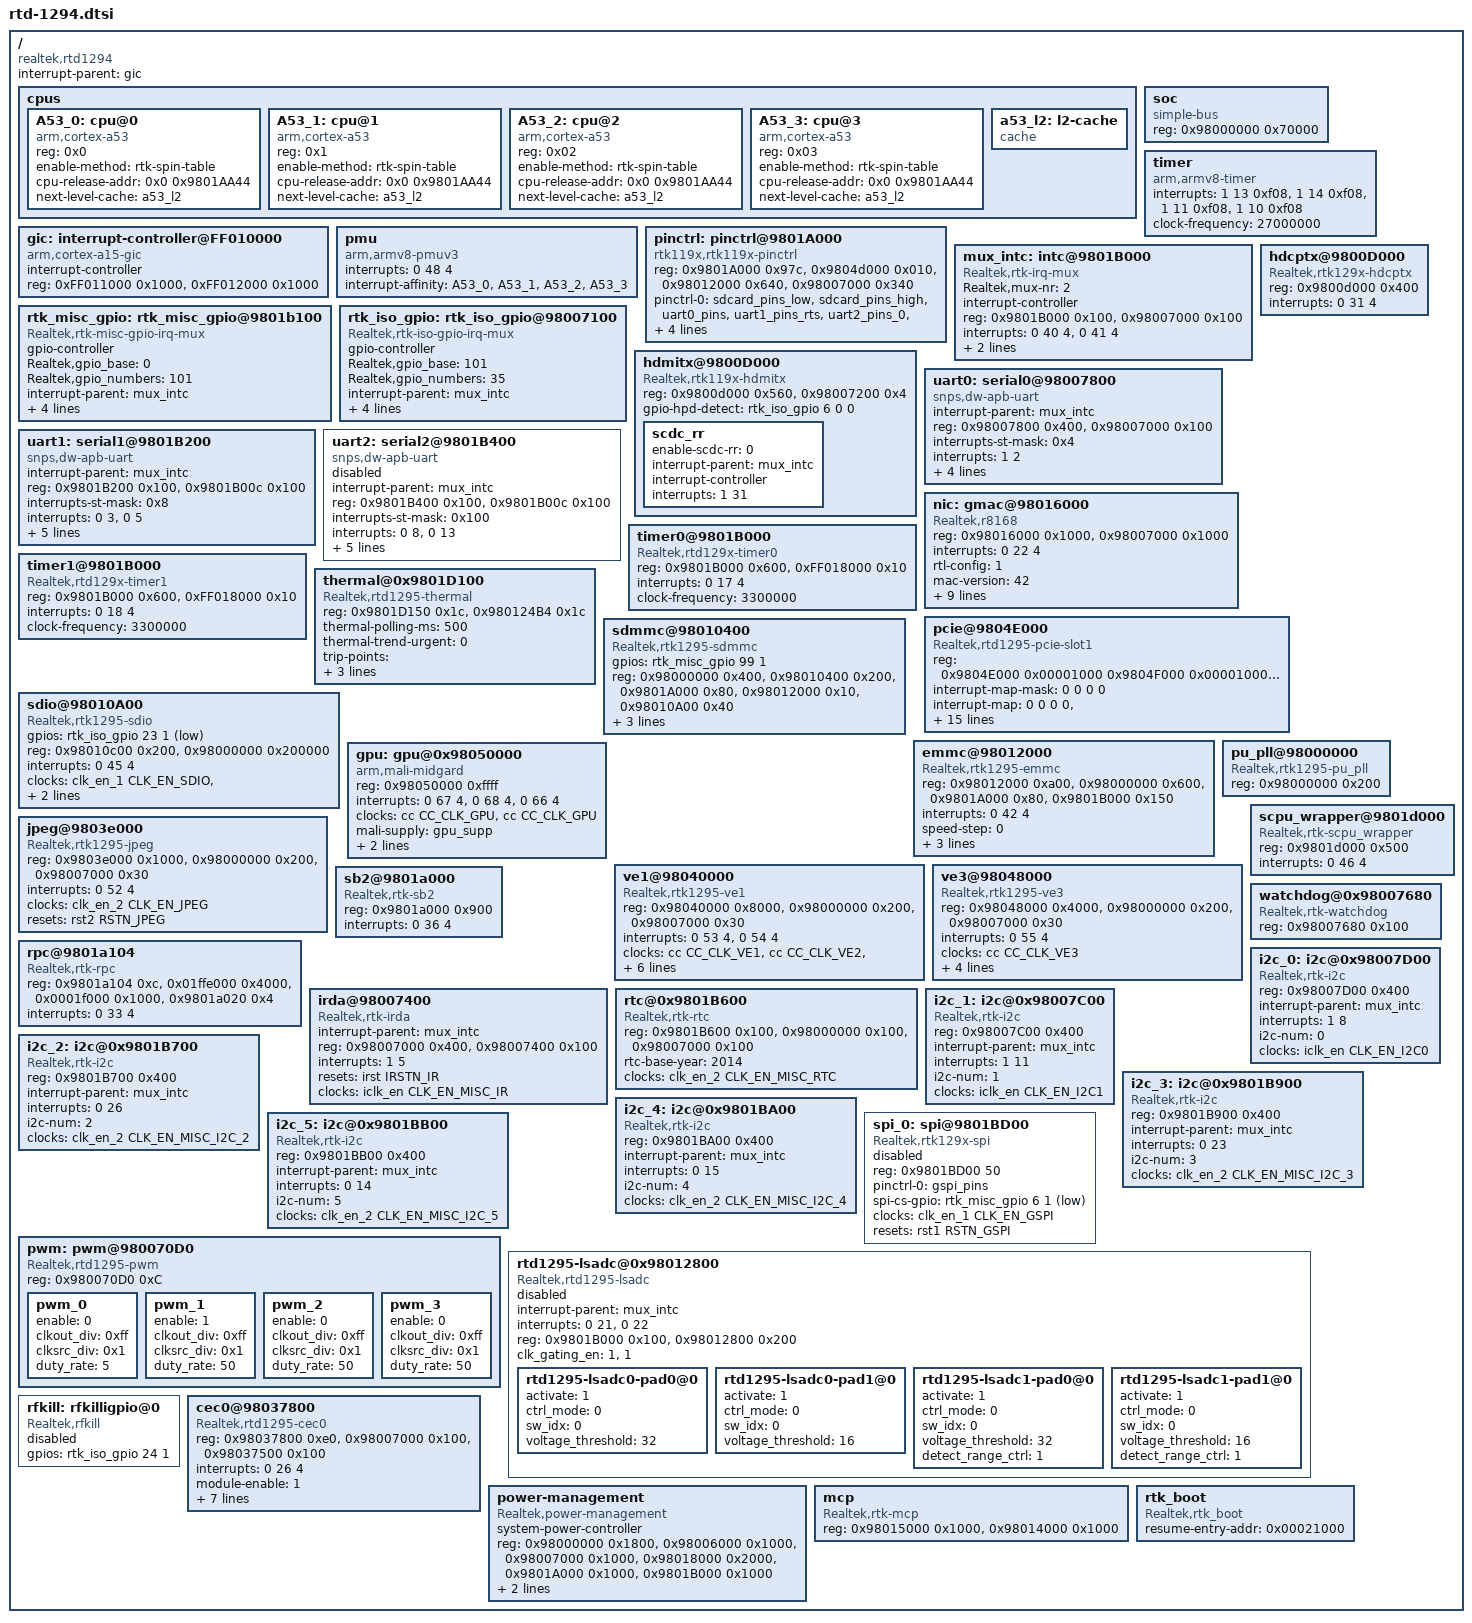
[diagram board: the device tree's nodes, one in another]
#include <dt-bindings/interrupt-controller/irq.h>
#include <dt-bindings/interrupt-controller/arm-gic.h>
/include/ "rtd-1295-pinctrl.dtsi"
/include/ "rtd-1295-irT377.dtsi"
/include/ "rtd-1294-usb.dtsi"
/include/ "rtd-129x-gpu-dvfs.dtsi"
#include "rtd-129x-common.dtsi"
/include/ "rtd-129x-dcsys-debug.dtsi"

/{

    compatible = "realtek,rtd1294";
    interrupt-parent = <&gic>;
    #address-cells = <1>;
    #size-cells = <1>;

    cpus {
        #address-cells = <1>;
        #size-cells = <0>;

        A53_0: cpu@0 {
            device_type = "cpu";
            compatible = "arm,cortex-a53", "arm,armv8";
            reg = <0x0>;
            /*enable-method = "psci";*/
            enable-method = "rtk-spin-table";
            cpu-release-addr = <0x0 0x9801AA44>;
            next-level-cache = <&a53_l2>;
        };

        A53_1: cpu@1 {
            device_type = "cpu";
            compatible = "arm,cortex-a53", "arm,armv8";
            reg = <0x1>;
            /*enable-method = "psci";*/
            enable-method = "rtk-spin-table";
            cpu-release-addr = <0x0 0x9801AA44>;
            next-level-cache = <&a53_l2>;
        };

        A53_2: cpu@2 {
            device_type = "cpu";
            compatible = "arm,cortex-a53", "arm,armv8";
            reg = <0x02>;
            /*enable-method = "psci";*/
            enable-method = "rtk-spin-table";
            cpu-release-addr = <0x0 0x9801AA44>;
            next-level-cache = <&a53_l2>;
        };

        A53_3: cpu@3 {
            device_type = "cpu";
            compatible = "arm,cortex-a53", "arm,armv8";
            reg = <0x03>;
            /*enable-method = "psci";*/
            enable-method = "rtk-spin-table";
            cpu-release-addr = <0x0 0x9801AA44>;
            next-level-cache = <&a53_l2>;
        };

        a53_l2: l2-cache {
            compatible = "cache";
        };
    };

    soc {
        #address-cells = <1>;
        #size-cells = <1>;
        reg = <0x98000000 0x70000>;
        compatible = "simple-bus";
        device_type = "soc";
        ranges;
    };

    timer {
        compatible = "arm,armv8-timer";
        interrupts = <1 13 0xf08>,
                     <1 14 0xf08>,
                     <1 11 0xf08>,
                     <1 10 0xf08>;
        clock-frequency = <27000000>;
    };

    gic: interrupt-controller@FF010000 {
        compatible = "arm,cortex-a15-gic";
        #interrupt-cells = <3>;
        interrupt-controller;
        reg = <0xFF011000 0x1000>,
              <0xFF012000 0x1000>;
    };

    pmu {
        compatible = "arm,armv8-pmuv3";
        interrupts = <0 48 4>;
        interrupt-affinity = <&A53_0>,
                             <&A53_1>,
                             <&A53_2>,
                             <&A53_3>;
    };

    pinctrl: pinctrl@9801A000 {
        compatible = "rtk119x,rtk119x-pinctrl";
        reg = <0x9801A000 0x97c>, <0x9804d000 0x010>, <0x98012000 0x640>, <0x98007000 0x340>;
        #gpio-range-cells = <3>;

        pinctrl-names = "default";
        pinctrl-0 = <&sdcard_pins_low>,
                    <&sdcard_pins_high>,
                    <&uart0_pins>,
                    <&uart1_pins_rts>,
                    <&uart2_pins_0>,
                    <&i2c_pins_0>,
                    <&i2c_pins_1>,
                    <&i2c_pins_5>,
                    <&i2c_pins_6>,
                    <&pcie1_clk_pins>,
                    <&pcie2_clk_pins>,
                    <&rgmii0_pins>,
                    <&ir_rx_pins>,
                    <&ir_tx_pins>,
                    <&spdif_pins>,
                    <&pwm0_0_pins>,
                    <&etn_led_pins>;
        status = "okay";
    };

    mux_intc: intc@9801B000 {
        compatible = "Realtek,rtk-irq-mux";
        Realtek,mux-nr = <2>;
        #interrupt-cells = <2>;
        interrupt-controller;
        reg = <0x9801B000 0x100>, /* MISC_TOP MISC_ISO */
              <0x98007000 0x100>;
        interrupts = <0 40 4>, <0 41 4>;
        intr-status = <0xc>, <0x0>;
        intr-en = <0x80>, <0x40>;
        status = "okay";
    };

    rtk_misc_gpio: rtk_misc_gpio@9801b100 {
        compatible = "Realtek,rtk-misc-gpio-irq-mux";
        gpio-controller;
        #gpio-cells = <3>; /*must be the same with gpiochip.of_gpio_n_cells*/
        Realtek,gpio_base = <0>;
        Realtek,gpio_numbers = <101>;
        interrupt-parent = <&mux_intc>;
        #interrupt-cells = <1>;
        interrupt-controller;
        interrupts = <0 19>, <0 20>; /*GPIOA_INT   GPIODA_INT*/
        reg = <0x9801b000 0x100>, <0x9801b100 0x100>; /* MISC_SYS MISC_GPIO*/
        gpio-ranges = <&pinctrl 0 0 101>;
        status = "okay";
    };

    rtk_iso_gpio: rtk_iso_gpio@98007100 {
        compatible = "Realtek,rtk-iso-gpio-irq-mux";
        gpio-controller;
        #gpio-cells = <3>;
        Realtek,gpio_base = <101>;
        Realtek,gpio_numbers = <35>;
        interrupt-parent = <&mux_intc>;
        #interrupt-cells = <1>;
        interrupt-controller;
        interrupts = <1 19>, <1 20>; /*GPIOA_INT   GPIODA_INT*/
        reg = <0x98007000 0x100>, <0x98007100 0x100>; /* ISO_SYS ISO_GPIO*/
        gpio-ranges = <&pinctrl 0 101 35>;
        status = "okay";
    };

	hdmitx@9800D000 {
		compatible = "Realtek,rtk119x-hdmitx";
		reg = <0x9800d000 0x560>,<0x98007200 0x4>; /* HDMITX, I2C1_REQ_CTRL */
		gpio-hpd-detect = <&rtk_iso_gpio 6 0 0>; /* Hotplug detect pin */
		//gpio-audio-mute = <&rtk_misc_gpio 100 1 1>; /* Audio DAC mute control */
		status = "okay";

		scdc_rr {
			enable-scdc-rr = <0>;
			interrupt-parent = <&mux_intc>;
			#interrupt-cells = <1>;
			interrupt-controller;
			interrupts = <1 31>;
		};
	};

    hdcptx@9800D000 {
        compatible = "Realtek,rtk129x-hdcptx";
        reg = <0x9800d000 0x400>;
        interrupts = <0 31 4>; /*gen Ri*/
        status = "okay";
    };

    uart0: serial0@98007800 {
        compatible = "snps,dw-apb-uart";
        interrupt-parent = <&mux_intc>;
        reg = <0x98007800 0x400>,
              <0x98007000 0x100>;
        interrupts-st-mask = <0x4>;
        interrupts = <1 2>;
        reg-shift = <2>;
        reg-io-width = <4>;
        clocks = <&iclk_en CLK_EN_MISC_UR0>;
        clock-frequency = <3300000>; /* This value must be override by the board. */
        status = "okay";
    };

    uart1: serial1@9801B200 {
        compatible = "snps,dw-apb-uart";
        interrupt-parent = <&mux_intc>;
        reg = <0x9801B200 0x100>,
              <0x9801B00c 0x100>;
        interrupts-st-mask = <0x8>;
        interrupts = <0 3>, <0 5>; /*UR1_INT and UR1_TO_INT*/
        reg-shift = <2>;
        reg-io-width = <4>;
        clocks = <&clk_en_2 CLK_EN_UR1>;
        resets = <&rst2 RSTN_UR1>;
        /* This value must be overriden by the board. */
        clock-frequency = <0>;
        status = "okay";
    };

    uart2: serial2@9801B400 {
        compatible = "snps,dw-apb-uart";
        interrupt-parent = <&mux_intc>;
        reg = <0x9801B400 0x100>,
              <0x9801B00c 0x100>;
        interrupts-st-mask = <0x100>;
        interrupts = <0 8>, <0 13>; /*UR2_INT and UR2_TO_INT*/
        reg-shift = <2>;
        reg-io-width = <4>;
        clocks = <&clk_en_2 CLK_EN_UR2>;
        resets = <&rst2 RSTN_UR2>;
        /* This value must be overriden by the board. */
        clock-frequency = <0>;
        status = "disabled"; /* Disable UR2 first since we don't use it now */
    };

    nic: gmac@98016000 {
        compatible = "Realtek,r8168";
        reg = <0x98016000 0x1000>,
              <0x98007000 0x1000>;
        interrupts = <0 22 4>;
        rtl-config = <1>;
        mac-version = <42>; /* RTL_GIGA_MAC_VER_42 */
        rtl-features = <2>; /* BIT(2) GMii */
        output-mode = <0>; /* 0:embedded PHY, 1:RGMII to MAC, 2:RGMII to PHY */
        rgmii-voltage = <1>; /* 1:1.8V, 2: 2.5V, 3:3.3V */
        rgmii-tx-delay = <0>; /* 0: 0ns, 1: 2ns */
        rgmii-rx-delay = <0>; /* 0: 0ns, 1: 2ns */
        ext-phy-id = <1>; /* 0 ~ 31, only valid when output-mode = 2 */
	clocks = <&iclk_en CLK_EN_ETN_250M>,
		<&iclk_en CLK_EN_ETN_SYS>;
	clock-names = "etn_250m",
		"etn_sys";
	resets = <&irst IRSTN_GMAC>,
		<&irst IRSTN_GPHY>;
	reset-names = "gmac",
		"gphy";
        status = "okay";
    };

    timer0@9801B000 {
        compatible = "Realtek,rtd129x-timer0";
        reg = <0x9801B000 0x600>,
              <0xFF018000 0x10>;
        interrupts = <0 17 4>;
        clock-frequency = <3300000>;
        status = "okay";
    };

    timer1@9801B000 {
        compatible = "Realtek,rtd129x-timer1";
        reg = <0x9801B000 0x600>,
              <0xFF018000 0x10>;
        interrupts = <0 18 4>;
        clock-frequency = <3300000>;
        status = "okay";
    };

    thermal@0x9801D100 {
        compatible = "Realtek,rtd1295-thermal";
        reg = <0x9801D150 0x1c>,
              <0x980124B4 0x1c>;
        thermal-polling-ms = <500>;
        thermal-trend-urgent = <0>;
        trip-points = <
            /* CPU */ 105      3    0      0
            /* CPU */ 115      3    0      1
            /* 2 */   120      7    1      0
            /* 3 */   130      0    3      0
            /* GPU */  95      5    4      2
            /* GPU */ 100      5    4      5
        >;
        /* freq range (KHz) to each trip point */
        cpufreq,freqs = <
            1300000   800000 /* bind to trip-point 0 */
             700000   300000 /* bind to trip-point 1 */
        >;
        /* cpu core list used by the cooling device */
        cpu-core,cpu-list = <&A53_3>, <&A53_2>, <&A53_1>;
        status = "okay";
    };


    pcie@9804E000 {
        compatible = "Realtek,rtd1295-pcie-slot1";
        reg = <0x9804E000 0x00001000
               0x9804F000 0x00001000
               0x9801C600 0x00000100
               0x9801A000 0x00000300
               0x98012000 0x00001000>;
        interrupt-names = "rtk-pcie1-intr";
        #interrupt-cells = <1>;
        interrupt-map-mask = <0 0 0 0>;
        interrupt-map = <0 0 0 0 &gic GIC_SPI 61 IRQ_TYPE_LEVEL_HIGH>;
        bus-range = <0x00 0xff>;
        linux,pci-domain = <0>;
        device_type = "pci";
        gpios = <&rtk_misc_gpio 18 1 0>;
        #size-cells = <2>;
        #address-cells = <3>;
        num-lanes = <1>;
        ranges = <0x02000000 0x00000000 0xC0000000  0xC0000000 0x00000000 0x01000000
                  0x01000000 0x00000000 0x00030000  0x00030000 0x00000000 0x00010000>;
	debug-mode = <0>;
	resets = <&rst2 RSTN_PCIE0>,
		<&rst2 RSTN_PCIE0_CORE>,
		<&rst2 RSTN_PCIE0_POWER>,
		<&rst2 RSTN_PCIE0_NONSTITCH>,
		<&rst2 RSTN_PCIE0_STITCH>,
		<&rst2 RSTN_PCIE0_PHY>,
		<&rst4 RSTN_PCIE0_PHY_MDIO>;
	reset-names = "rstn",
		"core",
		"power",
		"nonstitch",
		"stitch",
		"phy",
		"phy_mdio";
	clocks = <&clk_en_1 CLK_EN_PCIE0>;
        status = "okay";
        phys_a = <0x31810801>,
		<0xB2001101>,
		<0x00100001>;
	phys_b = <0x00000003>,
		<0x00900001>,
                <0x40080401>,
                <0x5AC10801>,
                <0x32b40f01>,
                <0x72001101>;
    };

    sdio@98010A00 {
        compatible = "Realtek,rtk1295-sdio";
        gpios = <&rtk_iso_gpio 23 1 1>;
        reg = <0x98010c00 0x200>,
              <0x98000000 0x200000>;
        interrupts = <0 45 4>;
	clocks = <&clk_en_1 CLK_EN_SDIO>,
		 <&clk_en_1 CLK_EN_SDIO_IP>;
	clock-names = "sdio",
		"sdio_ip";
	resets = <&rst2 RSTN_SDIO>;
        status = "okay";
    };

    sdmmc@98010400 {
        compatible = "Realtek,rtk1295-sdmmc";
        gpios = <&rtk_misc_gpio 99 1 0>; /*sd power , output, default high  (poweroff) */
        reg = <0x98000000 0x400>, /* CRT */
              <0x98010400 0x200>, /* SDMMC */
              <0x9801A000 0x80>, /* BS2 */
              <0x98012000 0x10>, /* EMMC */
              <0x98010A00 0x40>; /* SDIO */
        interrupts = <0 44 4>;
	clocks = <&clk_en_1 CLK_EN_CR>,
		<&clk_en_1 CLK_EN_SD_IP>;
	clock-names = "cr",
		"sd_ip";
        status = "okay";
    };

    emmc@98012000 {
        compatible = "Realtek,rtk1295-emmc";
        reg = <0x98012000 0xa00>, /*EMMC*/
              <0x98000000 0x600>, /*CRT */
              <0x9801A000 0x80>, /*SB2*/
              <0x9801B000 0x150>; /*MISC*/
        interrupts = <0 42 4>;
        speed-step = <0>; /* 0: sdr50, 1: ddr50, 2: hs200 */
	clocks = <&clk_en_1 CLK_EN_EMMC>,
		<&clk_en_1 CLK_EN_EMMC_IP>,
		<&clk_en_1 CLK_EN_CR>;
	clock-names = "emmc",
		"emmc_ip",
		"cr";
	resets = <&rst2 RSTN_EMMC>;
	reset-names = "emmc";
        status = "okay";
    };

    gpu: gpu@0x98050000 {
        compatible = "arm,mali-midgard";
        reg = <0x98050000 0xffff>;
        interrupts = <0 67 4>, <0 68 4>, <0 66 4>;
        interrupt-names = "JOB", "MMU", "GPU";

	clocks = <&cc CC_CLK_GPU>, <&cc CC_CLK_GPU>;
	clock-names = "clk_mali", "clk_gpu";
	mali-supply = <&gpu_supp>;
	dcdc3-supply = <&gpu_supp>;
	resets = <&rst1 RSTN_GPU>;

        status = "okay";
    };

    pu_pll@98000000 {
        compatible = "Realtek,rtk1295-pu_pll";
        reg = <0x98000000 0x200>;
    };

    jpeg@9803e000 {
        compatible = "Realtek,rtk1295-jpeg";
        reg = <0x9803e000 0x1000>, <0x98000000 0x200>, <0x98007000 0x30>;
        interrupts = <0 52 4>;
	clocks = <&clk_en_2 CLK_EN_JPEG>;
	resets = <&rst2 RSTN_JPEG>;
        status = "okay";
    };

    ve1@98040000 {
        compatible = "Realtek,rtk1295-ve1";
        reg = <0x98040000 0x8000>, <0x98000000 0x200>, <0x98007000 0x30>;
        interrupts = <0 53 4>, <0 54 4>;
	clocks = <&cc CC_CLK_VE1>, <&cc CC_CLK_VE2>, <&cc CC_CLK_SYSH>;
	clock-names = "clk_ve1","clk_ve2", "clk_sysh";
	resets = <&rst1 RSTN_VE1>, <&rst1 RSTN_VE2>;
	reset-names = "ve1", "ve2";
	assigned-clocks =        <&cc CC_CLK_VE1>,  <&cc CC_CLK_VE2>;
	assigned-clock-parents = <&cc CC_CLK_SYSH>, <&cc CC_PLL_VE2>;
	assigned-clock-rates =   <0>,               <715000000>;
        status = "okay";
    };

    ve3@98048000 {
        compatible = "Realtek,rtk1295-ve3";
        reg = <0x98048000 0x4000>, <0x98000000 0x200>, <0x98007000 0x30>;
        interrupts = <0 55 4>;
	clocks = <&cc CC_CLK_VE3>;
	resets = <&rst1 RSTN_VE3>;
	assigned-clocks =        <&cc CC_CLK_VE3>;
	assigned-clock-parents = <&cc CC_PLL_VE1>;
	assigned-clock-rates =   <594000000>;
        status = "okay";
    };

    scpu_wrapper@9801d000 {
        compatible = "Realtek,rtk-scpu_wrapper";
        reg = <0x9801d000 0x500>;
        interrupts = <0 46 4>;
        status = "okay";
    };

    sb2@9801a000 {
        compatible = "Realtek,rtk-sb2";
        reg = <0x9801a000 0x900>;
        interrupts = <0 36 4>;
        status = "okay";
    };

    rpc@9801a104 {
        compatible = "Realtek,rtk-rpc";
        reg = <0x9801a104 0xc>, /* rpc intr en */
              <0x01ffe000 0x4000>, /* rpc ring buffer */
              <0x0001f000 0x1000>, /* rpc common */
              <0x9801a020 0x4>; /* rbus sync */
        interrupts = <0 33 4>;
        status = "okay";
    };

    irda@98007400 {
        compatible = "Realtek,rtk-irda";
        interrupt-parent = <&mux_intc>;
        reg = <0x98007000 0x400>, <0x98007400 0x100>;
        interrupts = <1 5>;
	resets = <&irst IRSTN_IR>;
	clocks = <&iclk_en CLK_EN_MISC_IR>;
        status = "okay";
    };

    rtc@0x9801B600 {
        compatible = "Realtek,rtk-rtc";
        reg = <0x9801B600 0x100>,
              <0x98000000 0x100>,
              <0x98007000 0x100>;
        rtc-base-year = <2014>;
        clocks = <&clk_en_2 CLK_EN_MISC_RTC>;
        status = "okay";
    };

    watchdog@0x98007680 {
        compatible = "Realtek,rtk-watchdog";
        reg = <0x98007680 0x100>;
        status = "okay";
    };

    i2c_0: i2c@0x98007D00 {
        compatible = "Realtek,rtk-i2c";
        reg = <0x98007D00 0x400>;
        interrupt-parent = <&mux_intc>;
        interrupts = <1 8>;
        i2c-num = <0>;
        status = "okay";
        #address-cells = <1>;
        #size-cells = <0>;
        clocks = <&iclk_en CLK_EN_I2C0>;
    };

    i2c_1: i2c@0x98007C00 {
        compatible = "Realtek,rtk-i2c";
        reg = <0x98007C00 0x400>;
        interrupt-parent = <&mux_intc>;
        interrupts = <1 11>;
        i2c-num = <1>;
        status = "okay";
        #address-cells = <1>;
        #size-cells = <0>;
        clocks = <&iclk_en CLK_EN_I2C1>;
    };

    i2c_2: i2c@0x9801B700 {
        compatible = "Realtek,rtk-i2c";
        reg = <0x9801B700 0x400>;
        interrupt-parent = <&mux_intc>;
        interrupts = <0 26>;
        i2c-num = <2>;
        status = "okay";
        #address-cells = <1>;
        #size-cells = <0>;
        clocks = <&clk_en_2 CLK_EN_MISC_I2C_2>;
    };

    i2c_3: i2c@0x9801B900 {
        compatible = "Realtek,rtk-i2c";
        reg = <0x9801B900 0x400>;
        interrupt-parent = <&mux_intc>;
        interrupts = <0 23>;
        i2c-num = <3>;
        status = "okay";
        #address-cells = <1>;
        #size-cells = <0>;
        clocks = <&clk_en_2 CLK_EN_MISC_I2C_3>;
    };

    i2c_4: i2c@0x9801BA00 {
        compatible = "Realtek,rtk-i2c";
        reg = <0x9801BA00 0x400>;
        interrupt-parent = <&mux_intc>;
        interrupts = <0 15>;
        i2c-num = <4>;
        status = "okay";
        #address-cells = <1>;
        #size-cells = <0>;
        clocks = <&clk_en_2 CLK_EN_MISC_I2C_4>;
    };

    i2c_5: i2c@0x9801BB00 {
        compatible = "Realtek,rtk-i2c";
        reg = <0x9801BB00 0x400>;
        interrupt-parent = <&mux_intc>;
        interrupts = <0 14>;
        i2c-num = <5>;
        status = "okay";
        #address-cells = <1>;
        #size-cells = <0>;
        clocks = <&clk_en_2 CLK_EN_MISC_I2C_5>;
    };

    spi_0: spi@9801BD00 {
        compatible = "Realtek,rtk129x-spi";
        reg = <0x9801BD00 50>;
        pinctrl-names = "default";
        pinctrl-0 = <&gspi_pins>;
        spi-cs-gpio = <&rtk_misc_gpio 6 1 1>;
	clocks = <&clk_en_1 CLK_EN_GSPI>;
	resets = <&rst1 RSTN_GSPI>;
        status = "disabled";
    };

    pwm: pwm@980070D0 {
        compatible = "Realtek,rtd1295-pwm";
        #pwm-cells = <2>;
        reg = <0x980070D0 0xC>;
        status = "okay";
        pwm_0 {
            enable = <0>;
            clkout_div = <0xff>; //default OCD: from 0x0 to 0xff
            clksrc_div = <0x1>;  //default OSD: from 0x0 to 0xf
            duty_rate = <5>;  //default duty_rate 0 ~ 100
        };
        pwm_1 {
            enable = <1>;
            clkout_div = <0xff>; //default OCD: from 0x0 to 0xff
            clksrc_div = <0x1>;  //default OSD: from 0x0 to 0xf
            duty_rate = <50>;  //default duty_rate 0 ~ 100
        };
        pwm_2 {
            enable = <0>;
            clkout_div = <0xff>; //default OCD: from 0x0 to 0xff
            clksrc_div = <0x1>;  //default OSD: from 0x0 to 0xf
            duty_rate = <50>;  //default duty_rate 0 ~ 100
        };
        pwm_3 {
            enable = <0>;
            clkout_div = <0xff>; //default OCD: from 0x0 to 0xff
            clksrc_div = <0x1>;  //default OSD: from 0x0 to 0xf
            duty_rate = <50>;  //default duty_rate 0 ~ 100
        };
    };

    rtd1295-lsadc@0x98012800 {
        compatible = "Realtek,rtd1295-lsadc";
        interrupt-parent = <&mux_intc>;
        interrupts = <0 21>, <0 22>; /* LSADC0_INT, LSADC1_INT */
        reg = <0x9801B000 0x100>, /* MISC_TOP MISC_ISO */
              <0x98012800 0x200>; /* LSADC */
        status = "disabled";
        clk_gating_en = <1>, /* LSADC0 0:disable; 1:enable */
                        <1>; /* LSADC1 0:disable; 1:enable */

        rtd1295-lsadc0-pad0@0 {
            //compatible = "Realtek,rtd1295-lsadc0-pad0";
            activate = <1>; /* 0:in-activate; 1:activate */
            ctrl_mode = <0>; /* 0:Voltage mode; 1:Current mode*/
            sw_idx = <0>; /* 0:External input pin 0; 1:External input pin 1 */
            voltage_threshold = <32>; /* 8 bit : 0 ~ 255 */
        };

        rtd1295-lsadc0-pad1@0 {
            //compatible = "Realtek,rtd1295-lsadc0-pad1";
            activate = <1>; /* 0:in-activate; 1:activate */
            ctrl_mode = <0>; /* 0:Voltage mode; 1:Current mode*/
            sw_idx = <0>; /* 0:External input pin 0; 1:External input pin 1 */
            voltage_threshold = <16>; /* 8 bit : 0 ~ 255 */
        };

        rtd1295-lsadc1-pad0@0 {
            //compatible = "Realtek,rtd1295-lsadc1-pad0";
            activate = <1>; /* 0:in-activate; 1:activate */
            ctrl_mode = <0>; /* 0:Voltage mode; 1:Current mode*/
            sw_idx = <0>; /* 0:VDD; 1:GND */
            voltage_threshold = <32>; /* 8 bit : 0 ~ 255 */
            detect_range_ctrl = <1>; /* 0:0V ~ 1.024V; 1:0.5V ~ 1.524V */
        };

        rtd1295-lsadc1-pad1@0 {
            //compatible = "Realtek,rtd1295-lsadc1-pad1";
            activate = <1>; /* 0: in-activate; 1:activate */
            ctrl_mode = <0>; /* 0: Voltage mode; 1:Current mode*/
            sw_idx = <0>; /* 0:VDD; 1:GND */
            voltage_threshold = <16>; /* 8 bit : 0 ~ 255 */
            detect_range_ctrl = <1>; /* 0:0V ~ 1.024V; 1:0.5V ~ 1.524V */
        };
    };

    rfkill: rfkilligpio@0{
        compatible = "Realtek,rfkill";
        gpios = <&rtk_iso_gpio 24 1 0>; /*bt power , output, default low */
        status = "disabled";
    };

	cec0@98037800 {
		compatible = "Realtek,rtd1295-cec0";
		reg = <0x98037800 0xe0>,<0x98007000 0x100>,<0x98037500 0x100>;
		interrupts = <0 26 4>;
		module-enable = <1>;
		clocks = <&cc CC_CLK_SYS>,
			<&iclk_en CLK_EN_CBUS_OSC>,
			<&iclk_en CLK_EN_CBUS_SYS>,
			<&iclk_en CLK_EN_CBUSTX_SYS>,
			<&iclk_en CLK_EN_CBUSRX_SYS>;
		clock-names = "sys",
			"cbus_osc",
			"cbus_sys",
			"cbustx_sys",
			"cbusrx_sys";
		resets = <&irst IRSTN_CBUS>,
			<&irst IRSTN_CBUSTX>,
			<&irst IRSTN_CBUSRX>;
		reset-names = "cbus",
			"cbustx",
			"cbusrx";
		status = "okay";
	};

    power-management{
        compatible = "Realtek,power-management";
        system-power-controller;
        reg = <0x98000000 0x1800>, /* CRT */
              <0x98006000 0x1000>, /* AIO */
              <0x98007000 0x1000>, /* ISO */
              <0x98018000 0x2000>, /* TVE */
              <0x9801A000 0x1000>, /* SB2 */
              <0x9801B000 0x1000>; /* MISC */
        suspend-mode = <0>; // 0:SUSPEND_TO_RAM, 1:SUSPEND_TO_COOLBOOT, 2:SUSPEND_TO_WFI
        pwms = <&pwm 0 37878>;
        status = "okay";
    };

    mcp {
        compatible = "Realtek,rtk-mcp";
        reg = <0x98015000 0x1000>,
                    <0x98014000 0x1000>;
        status = "okay";
    };

    rtk_boot {
        compatible = "Realtek,rtk_boot";
        resume-entry-addr = <0x00021000>;
        status = "okay";
    };
};

